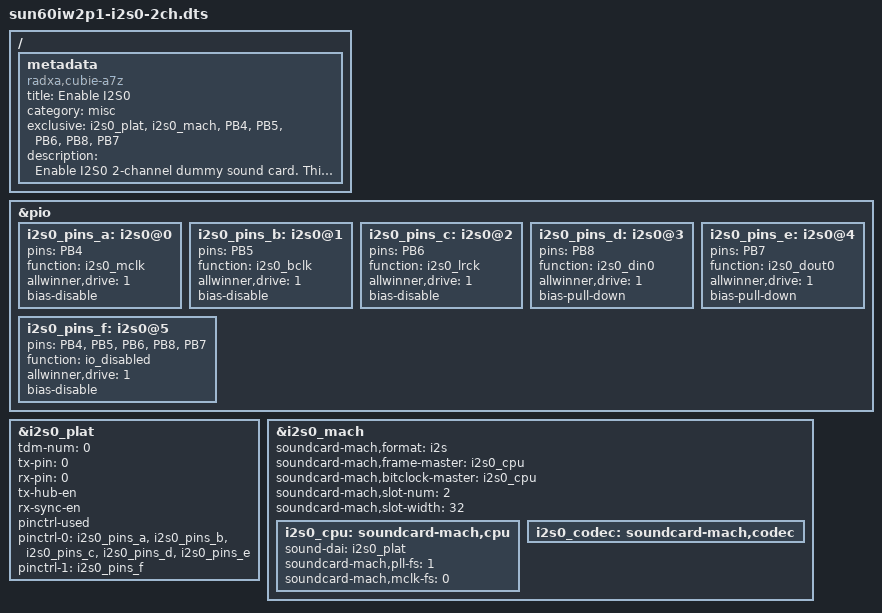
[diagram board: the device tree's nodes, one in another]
/dts-v1/;
/plugin/;

/{
	metadata {
		title = "Enable I2S0";
		compatible = "radxa,cubie-a7z";
		category = "misc";
		exclusive = "i2s0_plat", "i2s0_mach", "PB4", "PB5", "PB6", "PB8", "PB7";
		description = "Enable I2S0 2-channel dummy sound card.
This overlay is only for demonstration purpose.
It does not support any specific hardware device.";
	};
};

&pio {
	/* i2s0 pins */
	i2s0_pins_a: i2s0@0 {
		pins = "PB4";
		function = "i2s0_mclk";
		allwinner,drive = <1>;
		bias-disable;
	};

	i2s0_pins_b: i2s0@1 {
		pins = "PB5";
		function = "i2s0_bclk";
		allwinner,drive = <1>;
		bias-disable;
	};

	i2s0_pins_c: i2s0@2 {
		pins = "PB6";
		function = "i2s0_lrck";
		allwinner,drive = <1>;
		bias-disable;
	};

	i2s0_pins_d: i2s0@3 {
		pins = "PB8";
		function = "i2s0_din0";
		allwinner,drive = <1>;
		bias-pull-down;
	};

	i2s0_pins_e: i2s0@4 {
		pins = "PB7";
		function = "i2s0_dout0";
		allwinner,drive = <1>;
		bias-pull-down;
	};

	i2s0_pins_f: i2s0@5 {
		pins = "PB4", "PB5", "PB6", "PB8", "PB7";
		function = "io_disabled";
		allwinner,drive = <1>;
		bias-disable;
	};
};

&i2s0_plat {
	tdm-num = <0>;
	tx-pin = <0>;
	rx-pin = <0>;

	tx-hub-en;
	rx-sync-en;

	pinctrl-used;
	pinctrl-names = "default","sleep";
	pinctrl-0 = <&i2s0_pins_a &i2s0_pins_b &i2s0_pins_c &i2s0_pins_d &i2s0_pins_e>;
	pinctrl-1 = <&i2s0_pins_f>;

	status = "okay";
};

&i2s0_mach {
	soundcard-mach,format = "i2s";
	soundcard-mach,frame-master	= <&i2s0_cpu>;
	soundcard-mach,bitclock-master = <&i2s0_cpu>;
	/* soundcard-mach,frame-inversion; */
	/* soundcard-mach,bitclock-inversion; */
	soundcard-mach,slot-num = <2>;
	soundcard-mach,slot-width = <32>;
	status = "okay";
	i2s0_cpu: soundcard-mach,cpu {
		sound-dai = <&i2s0_plat>;
		soundcard-mach,pll-fs	= <1>;
		soundcard-mach,mclk-fs	= <0>;
	};
	i2s0_codec: soundcard-mach,codec {
	};
};
